# K1921VK035 register map
Vendor: NIIET; Series: K1921VKx; File version: 2.10
CPU: CM4 r0p1, little endian, MPU, FPU, 3 interrupt priority bits
Registers are 32-bit, read-write, reset 0x0 unless marked. A register's access mark holds for its fields unless they carry their own. Offsets are from the block's base; [hi:lo] are bit positions; lines under a group give offsets from that group; {n}, {i} and the like mark numbered series.

## DMA — DMA control registers
Base 0x40044000
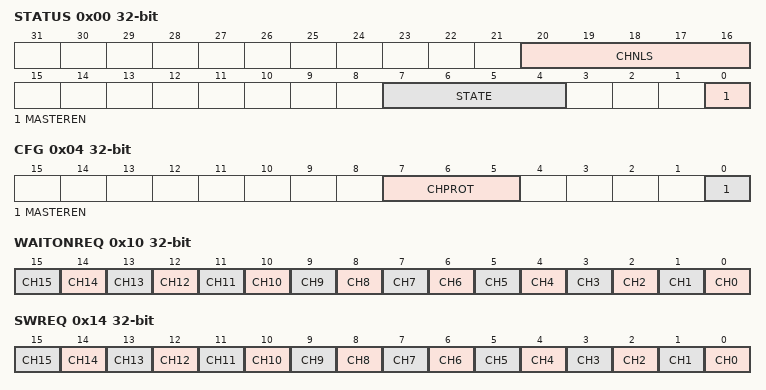
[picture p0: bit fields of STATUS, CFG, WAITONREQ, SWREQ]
0x00 STATUS ro — Status DMA register
  [20:16] CHNLS — Number channel DMA (write: N-1)
  [7:4] STATE — State of DMA
    on read: 0=Free (At rest); 1=ReadConfigData (Reading the config data structure); 2=ReadSrcDataEndPtr (Reading sourse data end pointer); 3=ReadDstDataEndPtr (Reading destination data end pointer); 4=ReadSrcData (Reading source data); 5=WrireDstData (Writing data to the destination); 6=WaitReq (Waiting for a request); 7=WriteConfigData (Write config structure of the channel); 8=Pause (Suspended); 9=Done (Executed); 10=PeriphScatGath (mode "peripheral scather-gather")
  [0] MASTEREN — Indicate enable DMA
0x04 CFG wo — DMA configuration register
  [7:5] CHPROT — Sets the AHB-Lite protection
  [0] MASTEREN — Enable DMA
0x08 BASEPTR — Channel control data base pointer
  [31:0] VAL
0x0C ALTBASEPTR ro — Channel alternate control data base pointer
  [31:0] VAL
0x10 WAITONREQ ro — Channel wait on request status
  [n] CH{n} (n=0..15) — Returns the status of the DMA request signals
0x14 SWREQ wo — Channel software request
  [n] CH{n} (n=0..15) — Set software request on channel
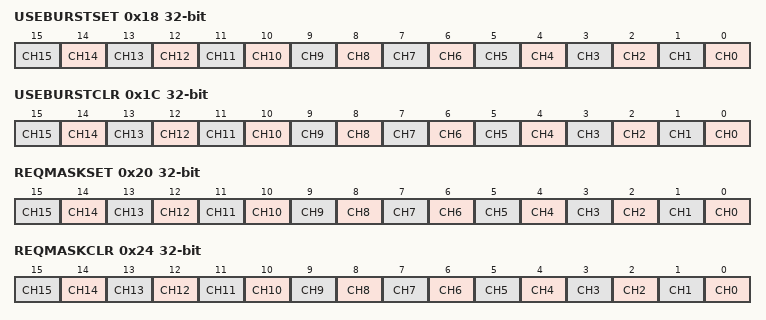
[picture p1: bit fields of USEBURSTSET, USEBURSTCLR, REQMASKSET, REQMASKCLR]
0x18 USEBURSTSET — Channel useburst set
  [n] CH{n} (n=0..15) — Enable single requests
0x1C USEBURSTCLR wo — Channel useburst clear
  [n] CH{n} (n=0..15) — Disable single requests
0x20 REQMASKSET — Channel request mask set
  [n] CH{n} (n=0..15) — External requests are enabled for channel
0x24 REQMASKCLR wo — Channel request mask clear
  [n] CH{n} (n=0..15) — External requests are disabled for channel
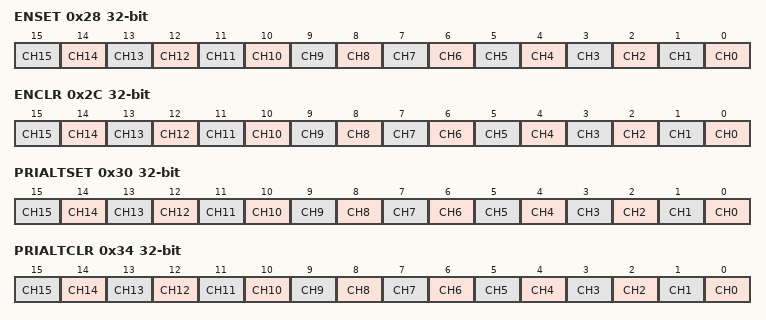
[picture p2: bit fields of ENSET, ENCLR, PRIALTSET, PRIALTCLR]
0x28 ENSET — Channel enable set
  [n] CH{n} (n=0..15) — Enable channel
0x2C ENCLR wo — Channel enable clear
  [n] CH{n} (n=0..15) — Disable channel
0x30 PRIALTSET — Channel primary-alternate set
  [n] CH{n} (n=0..15) — Set primary / alternate channel control data structure
0x34 PRIALTCLR wo — Channel primary-alternate clear
  [n] CH{n} (n=0..15) — Clear primary / alternate channel control data structure
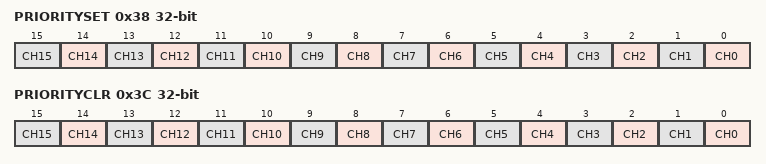
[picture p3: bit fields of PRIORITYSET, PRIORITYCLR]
0x38 PRIORITYSET — Channel priority set
  [n] CH{n} (n=0..15) — Set the priority of channel
0x3C PRIORITYCLR wo — Channel priority clear
  [n] CH{n} (n=0..15) — Clear the priority
0x4C ERRCLR — Bus error register
  [0] VAL — Indicate Error on bus AHB-Lite

## MFLASH — Mainflash control registers
Base 0x40030000
0x00 ADDR — Address Register
  [31:0] VAL — Address value for flash operations
{0x4+4i} DATA[{i}] (i=0..1) group
  0x00 DATA
    [31:0] VAL — Data register value for flash operations
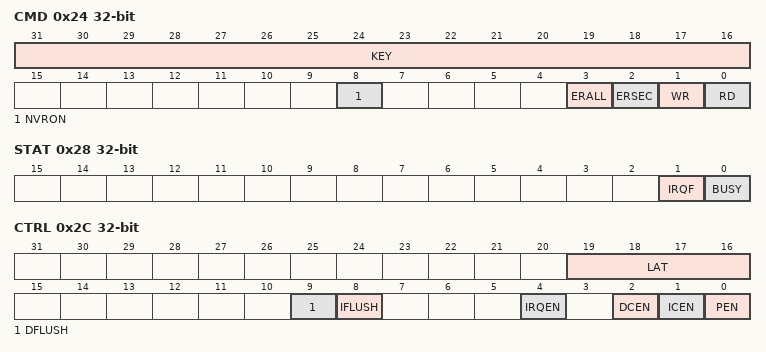
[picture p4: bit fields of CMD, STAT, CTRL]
0x24 CMD — Command Register
  [31:16] KEY — Magic Key for flash access "C0DE"
    0xC0DE=Access (magic Key for flash access)
  [8] NVRON — NVR access bit
  [3] ERALL — Erase all enable command
  [2] ERSEC — Erase sector enable command
  [1] WR — Write enable command
  [0] RD — Read enable command
0x28 STAT — Status Register
  [1] IRQF — IRQ Flag set when command done. Set by hardware only if IRQEN bit is set.
  [0] BUSY ro — Busy status bit when command is processing
0x2C CTRL — Control Register
  [19:16] LAT — Flash latency
  [9] DFLUSH wo — Flush D-Cache request bit
  [8] IFLUSH wo — Flush I-Cache request bit
  [4] IRQEN — Interrupt enable bit
  [2] DCEN — D-Cache enable bit
  [1] ICEN — I-Cache enable bit
  [0] PEN — Prefetch enable bit
0x34 ICSTAT ro — ICACHE Status Register
  [0] BUSY — Busy flag for I-Cache flush/test system
0x38 DCSTAT ro — DCACHE Status Register
  [0] BUSY — Busy flag for D-Cache flush/test system
0x78 BDIS — Boot Mode Disable register
  [0] BMDIS — Disable boot mode after system reset command

## ECAP0 — ECAP controller registers
Base 0x40051000
Same registers: ECAP1 0x40052000, ECAP2 0x40053000
0x00 TSCTR — Counter register
  [31:0] VAL
0x04 CTRPHS — Counter Phase Sync register
  [31:0] VAL
{0x8+4i} CAP{i} (i=0..3) — Capture register {i}
  [31:0] VAL — Capture {i} value in CAP mode
0x08 PRD (alternate view of CAP0) — Period register
  [31:0] VAL — Period value in APWM mode
0x0C CMP (alternate view of CAP1) — Compare register
  [31:0] VAL — Compare value in APWM mode
0x10 PRDSHDW (alternate view of CAP2) — Period shadow register
  [31:0] VAL — Period shadow value in APWM mode
0x14 CMPSHDW (alternate view of CAP3) — Compare shadow register
  [31:0] VAL — Compare shadow value in APWM mode
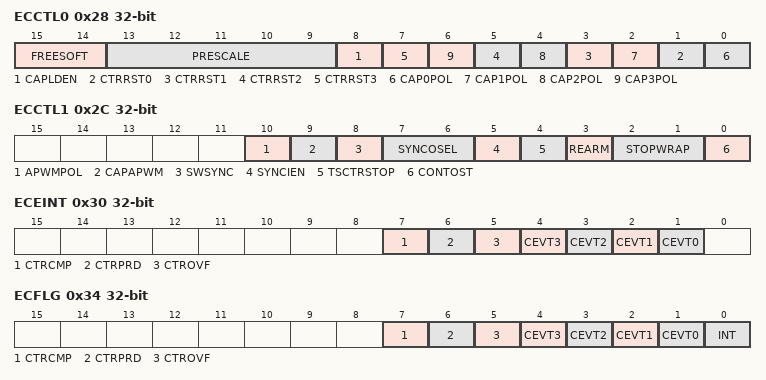
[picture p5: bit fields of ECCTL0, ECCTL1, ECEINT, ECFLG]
0x28 ECCTL0 — Capture control register 0
  [15:14] FREESOFT
    0=stop timer immedeatelly; 1=StopAtZero (stop timer when reach zero); 2=Free (normal work)
  [13:9] PRESCALE
  [8] CAPLDEN — enable capture
  [2n+1] CTRRST{n} (n=0..3) — Reset counter after event {n}
  [2n] CAP{n}POL (n=0..3) — Polarity select for capture {n}
0x2C ECCTL1 — Capture control register 1
  [10] APWMPOL — High/low level APWM
  [9] CAPAPWM — Capture mode or APWM mode
  [8] SWSYNC — Software timers sync
  [7:6] SYNCOSEL
    0=Bypass (sync in connected with sync out); 1=CTREqPrd (sync out generated when CTR = PRD); 2=Disable (sync out generate disabled)
  [5] SYNCIEN — Sync in enable
  [4] TSCTRSTOP — Enable Timer
  [3] REARM — Reset and enable controller, capture reg load
  [2:1] STOPWRAP
  [0] CONTOST — Capture mode
0x30 ECEINT — Interrupt mask register
  [7] CTRCMP — enable int CTR=CMP
  [6] CTRPRD — enable int CTR=PRD
  [5] CTROVF — enable int CTR_OVF
  [n+1] CEVT{n} (n=0..3) — enable int CEVT{n}
0x34 ECFLG ro — Interrupt status register
  [7] CTRCMP — Hap interrupt CTR=CMP
  [6] CTRPRD — Hap interrupt CTR=PRD
  [5] CTROVF — Hap interrupt CTROVF
  [n+1] CEVT{n} (n=0..3) — Hap interrupt CEVT{n}
  [0] INT — indicate global interrupt
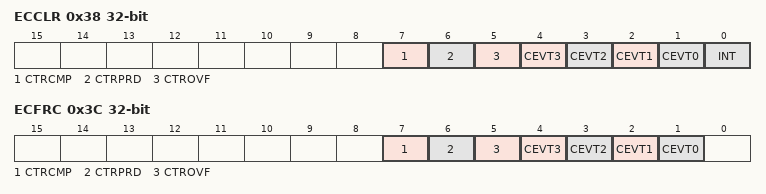
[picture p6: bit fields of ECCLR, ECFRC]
0x38 ECCLR — Clear interrupt register
  [7] CTRCMP — reset intstatus
  [6] CTRPRD — reset intstatus
  [5] CTROVF — reset intstatus
  [n+1] CEVT{n} (n=0..3) — reset intstatus
  [0] INT — reset global interrupt
0x3C ECFRC — Force interrupt register
  [7] CTRCMP — gen test interrupt
  [6] CTRPRD — gen test interrupt
  [5] CTROVF — gen test interrupt
  [n+1] CEVT{n} (n=0..3) — gen test interrupt
0x40 PEINT — Active interrupt status register
  [0] PEINT — active interrupt flag
